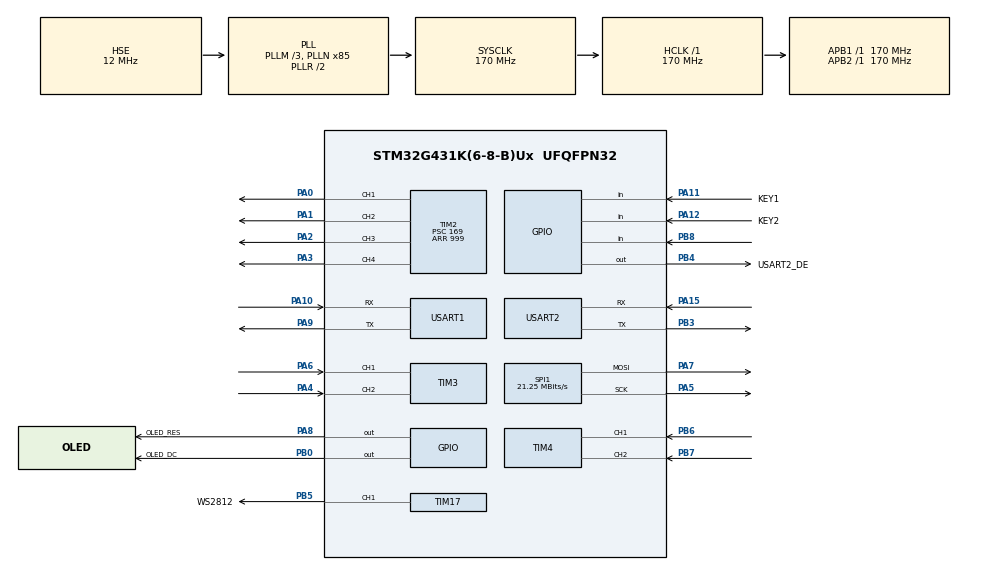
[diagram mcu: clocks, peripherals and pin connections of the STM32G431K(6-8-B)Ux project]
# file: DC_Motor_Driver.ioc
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Dma.Request0=USART1_RX
Dma.Request1=SPI1_TX
Dma.Request2=TIM17_CH1
Dma.Request3=USART2_RX
Dma.SPI1_TX.1.Direction=DMA_MEMORY_TO_PERIPH
Dma.SPI1_TX.1.EventEnable=DISABLE
Dma.SPI1_TX.1.Instance=DMA2_Channel1
Dma.SPI1_TX.1.MemDataAlignment=DMA_MDATAALIGN_BYTE
Dma.SPI1_TX.1.MemInc=DMA_MINC_ENABLE
Dma.SPI1_TX.1.Mode=DMA_NORMAL
Dma.SPI1_TX.1.PeriphDataAlignment=DMA_PDATAALIGN_BYTE
Dma.SPI1_TX.1.PeriphInc=DMA_PINC_DISABLE
Dma.SPI1_TX.1.Polarity=HAL_DMAMUX_REQ_GEN_RISING
Dma.SPI1_TX.1.Priority=DMA_PRIORITY_LOW
Dma.SPI1_TX.1.RequestNumber=1
Dma.SPI1_TX.1.SignalID=NONE
Dma.SPI1_TX.1.SyncEnable=DISABLE
Dma.SPI1_TX.1.SyncPolarity=HAL_DMAMUX_SYNC_NO_EVENT
Dma.SPI1_TX.1.SyncRequestNumber=1
Dma.SPI1_TX.1.SyncSignalID=NONE
Dma.TIM17_CH1.2.Direction=DMA_PERIPH_TO_MEMORY
Dma.TIM17_CH1.2.EventEnable=DISABLE
Dma.TIM17_CH1.2.Instance=DMA2_Channel2
Dma.TIM17_CH1.2.MemDataAlignment=DMA_MDATAALIGN_HALFWORD
Dma.TIM17_CH1.2.MemInc=DMA_MINC_ENABLE
Dma.TIM17_CH1.2.Mode=DMA_NORMAL
Dma.TIM17_CH1.2.PeriphDataAlignment=DMA_PDATAALIGN_HALFWORD
Dma.TIM17_CH1.2.PeriphInc=DMA_PINC_DISABLE
Dma.TIM17_CH1.2.Polarity=HAL_DMAMUX_REQ_GEN_RISING
Dma.TIM17_CH1.2.Priority=DMA_PRIORITY_LOW
Dma.TIM17_CH1.2.RequestNumber=1
Dma.TIM17_CH1.2.SignalID=NONE
Dma.TIM17_CH1.2.SyncEnable=DISABLE
Dma.TIM17_CH1.2.SyncPolarity=HAL_DMAMUX_SYNC_NO_EVENT
Dma.TIM17_CH1.2.SyncRequestNumber=1
Dma.TIM17_CH1.2.SyncSignalID=NONE
Dma.USART1_RX.0.Direction=DMA_PERIPH_TO_MEMORY
Dma.USART1_RX.0.EventEnable=DISABLE
Dma.USART1_RX.0.Instance=DMA1_Channel1
Dma.USART1_RX.0.MemDataAlignment=DMA_MDATAALIGN_BYTE
Dma.USART1_RX.0.MemInc=DMA_MINC_ENABLE
Dma.USART1_RX.0.Mode=DMA_NORMAL
Dma.USART1_RX.0.PeriphDataAlignment=DMA_PDATAALIGN_BYTE
Dma.USART1_RX.0.PeriphInc=DMA_PINC_DISABLE
Dma.USART1_RX.0.Polarity=HAL_DMAMUX_REQ_GEN_RISING
Dma.USART1_RX.0.Priority=DMA_PRIORITY_LOW
Dma.USART1_RX.0.RequestNumber=1
Dma.USART1_RX.0.SignalID=NONE
Dma.USART1_RX.0.SyncEnable=DISABLE
Dma.USART1_RX.0.SyncPolarity=HAL_DMAMUX_SYNC_NO_EVENT
Dma.USART1_RX.0.SyncRequestNumber=1
Dma.USART1_RX.0.SyncSignalID=NONE
Dma.USART2_RX.3.Direction=DMA_PERIPH_TO_MEMORY
Dma.USART2_RX.3.EventEnable=DISABLE
Dma.USART2_RX.3.Instance=DMA1_Channel2
Dma.USART2_RX.3.MemDataAlignment=DMA_MDATAALIGN_BYTE
Dma.USART2_RX.3.MemInc=DMA_MINC_ENABLE
Dma.USART2_RX.3.Mode=DMA_NORMAL
Dma.USART2_RX.3.PeriphDataAlignment=DMA_PDATAALIGN_BYTE
Dma.USART2_RX.3.PeriphInc=DMA_PINC_DISABLE
Dma.USART2_RX.3.Polarity=HAL_DMAMUX_REQ_GEN_RISING
Dma.USART2_RX.3.Priority=DMA_PRIORITY_LOW
Dma.USART2_RX.3.RequestNumber=1
Dma.USART2_RX.3.SignalID=NONE
Dma.USART2_RX.3.SyncEnable=DISABLE
Dma.USART2_RX.3.SyncPolarity=HAL_DMAMUX_SYNC_NO_EVENT
Dma.USART2_RX.3.SyncRequestNumber=1
Dma.USART2_RX.3.SyncSignalID=NONE
Mcu.Family=STM32G4
Mcu.Name=STM32G431K(6-8-B)Ux
Mcu.Package=UFQFPN32
NVIC.DMA1_Channel1_IRQn=true\:0\:0\:false\:false\:true\:false\:true\:true
NVIC.DMA1_Channel2_IRQn=true\:0\:0\:false\:false\:true\:false\:true\:true
NVIC.DMA2_Channel1_IRQn=true\:0\:0\:false\:false\:true\:false\:true\:true
NVIC.DMA2_Channel2_IRQn=true\:0\:0\:false\:false\:true\:false\:true\:true
NVIC.PriorityGroup=NVIC_PRIORITYGROUP_4
NVIC.TIM3_IRQn=true\:0\:0\:false\:false\:true\:true\:true\:true
NVIC.TIM4_IRQn=true\:0\:0\:false\:false\:true\:true\:true\:true
NVIC.TIM6_DAC_IRQn=true\:0\:0\:false\:false\:true\:true\:true\:true
NVIC.USART1_IRQn=true\:0\:0\:false\:false\:true\:true\:true\:true
NVIC.USART2_IRQn=true\:0\:0\:false\:false\:true\:true\:true\:true
PA0.Signal=S_TIM2_CH1
PA1.Signal=S_TIM2_CH2
PA10.Mode=Asynchronous
PA10.Signal=USART1_RX
PA11.GPIO_Label=KEY1
PA11.Signal=GPIO_Input
PA12.GPIO_Label=KEY2
PA12.Signal=GPIO_Input
PA13.Mode=Serial_Wire
PA13.Signal=SYS_JTMS-SWDIO
PA14.Mode=Serial_Wire
PA14.Signal=SYS_JTCK-SWCLK
PA15.Mode=Asynchronous
PA15.Signal=USART2_RX
PA2.Signal=S_TIM2_CH3
PA3.Signal=S_TIM2_CH4
PA4.Signal=S_TIM3_CH2
PA5.Mode=TX_Only_Simplex_Unidirect_Master
PA5.Signal=SPI1_SCK
PA6.Signal=S_TIM3_CH1
PA7.Mode=TX_Only_Simplex_Unidirect_Master
PA7.Signal=SPI1_MOSI
PA8.GPIO_Label=OLED_RES
PA8.Signal=GPIO_Output
PA9.Mode=Asynchronous
PA9.Signal=USART1_TX
PB0.GPIO_Label=OLED_DC
PB0.Signal=GPIO_Output
PB3.Mode=Asynchronous
PB3.Signal=USART2_TX
PB4.GPIO_Label=USART2_DE
PB4.Signal=GPIO_Output
PB5.GPIO_Label=WS2812
PB5.Signal=S_TIM17_CH1
PB6.Signal=S_TIM4_CH1
PB7.Signal=S_TIM4_CH2
PB8-BOOT0.Signal=GPIO_Input
PF0-OSC_IN.Mode=HSE-External-Oscillator
PF0-OSC_IN.Signal=RCC_OSC_IN
PF1-OSC_OUT.Mode=HSE-External-Oscillator
PF1-OSC_OUT.Signal=RCC_OSC_OUT
ProjectManager.HeapSize=0x200
ProjectManager.StackSize=0x400
ProjectManager.TargetToolchain=MDK-ARM V5.32
RCC.ADC12Freq_Value=170000000
RCC.AHBFreq_Value=170000000
RCC.APB1Freq_Value=170000000
RCC.APB1TimFreq_Value=170000000
RCC.APB2Freq_Value=170000000
RCC.APB2TimFreq_Value=170000000
RCC.CortexFreq_Value=170000000
RCC.EXTERNAL_CLOCK_VALUE=12288000
RCC.HCLKFreq_Value=170000000
RCC.HSE_VALUE=12000000
RCC.HSI48_VALUE=48000000
RCC.HSI_VALUE=16000000
RCC.LSE_VALUE=32768
RCC.PLLM=RCC_PLLM_DIV3
RCC.PLLN=85
RCC.PLLSourceVirtual=RCC_PLLSOURCE_HSE
RCC.SYSCLKFreq_VALUE=170000000
RCC.SYSCLKSource=RCC_SYSCLKSOURCE_PLLCLK
RCC.USBFreq_Value=170000000
RCC.VCOOutputFreq_Value=340000000
RTC.AsynchPrediv=31
RTC.SynchPrediv=999
SH.S_TIM17_CH1.0=TIM17_CH1,PWM Generation1 CH1
SH.S_TIM2_CH1.0=TIM2_CH1,PWM Generation1 CH1
SH.S_TIM2_CH2.0=TIM2_CH2,PWM Generation2 CH2
SH.S_TIM2_CH3.0=TIM2_CH3,PWM Generation3 CH3
SH.S_TIM2_CH4.0=TIM2_CH4,PWM Generation4 CH4
SH.S_TIM3_CH1.0=TIM3_CH1,Encoder_Interface
SH.S_TIM3_CH2.0=TIM3_CH2,Encoder_Interface
SH.S_TIM4_CH1.0=TIM4_CH1,Encoder_Interface
SH.S_TIM4_CH2.0=TIM4_CH2,Encoder_Interface
SPI1.BaudRatePrescaler=SPI_BAUDRATEPRESCALER_8
SPI1.CalculateBaudRate=21.25 MBits/s
SPI1.DataSize=SPI_DATASIZE_8BIT
SPI1.Direction=SPI_DIRECTION_2LINES
SPI1.Mode=SPI_MODE_MASTER
SPI1.VirtualType=VM_MASTER
TIM17.Channel=TIM_CHANNEL_1
TIM2.AutoReloadPreload=TIM_AUTORELOAD_PRELOAD_ENABLE
TIM2.Channel-PWM\ Generation1\ CH1=TIM_CHANNEL_1
TIM2.Channel-PWM\ Generation2\ CH2=TIM_CHANNEL_2
TIM2.Channel-PWM\ Generation3\ CH3=TIM_CHANNEL_3
TIM2.Channel-PWM\ Generation4\ CH4=TIM_CHANNEL_4
TIM2.PeriodNoDither=999
TIM2.Prescaler=169
TIM3.EncoderMode=TIM_ENCODERMODE_TI12
TIM3.IC1Polarity=TIM_ICPOLARITY_RISING
TIM3.IC2Polarity=TIM_ICPOLARITY_RISING
TIM4.EncoderMode=TIM_ENCODERMODE_TI12
TIM4.IC1Polarity=TIM_ICPOLARITY_RISING
TIM4.IC2Polarity=TIM_ICPOLARITY_RISING
TIM6.AutoReloadPreload=TIM_AUTORELOAD_PRELOAD_ENABLE
TIM6.PeriodNoDither=999
TIM6.Prescaler=16999
USART1.VirtualMode-Asynchronous=VM_ASYNC
USART2.VirtualMode-Asynchronous=VM_ASYNC
VP_RTC_VS_RTC_Activate.Mode=RTC_Enabled
VP_RTC_VS_RTC_Calendar.Mode=RTC_Calendar
VP_SYS_VS_DBSignals.Mode=DisableDeadBatterySignals
VP_TIM17_VS_ClockSourceINT.Mode=Enable_Timer
VP_TIM2_VS_ClockSourceINT.Mode=Internal
VP_TIM6_VS_ClockSourceINT.Mode=Enable_Timer
board=custom

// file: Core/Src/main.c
/* USER CODE BEGIN Header */
/* USER CODE END Header */
#include "main.h"
#include "dma.h"
#include "rtc.h"
#include "spi.h"
#include "tim.h"
#include "usart.h"
#include "gpio.h"

/* USER CODE BEGIN Includes */
#include "app_main.h"
/* USER CODE END Includes */

void SystemClock_Config(void);

int main(void)
{

  /* MCU Configuration--------------------------------------------------------*/

  /* Reset of all peripherals, Initializes the Flash interface and the Systick. */
  HAL_Init();

  /* Configure the system clock */
  SystemClock_Config();

  /* Initialize all configured peripherals */
  MX_GPIO_Init();
  MX_DMA_Init();
  MX_SPI1_Init();
  MX_TIM2_Init();
  MX_TIM3_Init();
  MX_TIM4_Init();
  MX_TIM17_Init();
  MX_USART1_UART_Init();
  MX_USART2_UART_Init();
  MX_TIM6_Init();
  MX_RTC_Init();
  /* USER CODE BEGIN 2 */

  APP_Main();
  /* USER CODE END 2 */

  /* Infinite loop */
  while (1)
  {

  }
}

void SystemClock_Config(void)
{
  RCC_OscInitTypeDef RCC_OscInitStruct = {0};
  RCC_ClkInitTypeDef RCC_ClkInitStruct = {0};

  /** Configure the main internal regulator output voltage
  */
  HAL_PWREx_ControlVoltageScaling(PWR_REGULATOR_VOLTAGE_SCALE1_BOOST);

  /** Initializes the RCC Oscillators according to the specified parameters
  * in the RCC_OscInitTypeDef structure.
  */
  RCC_OscInitStruct.OscillatorType = RCC_OSCILLATORTYPE_LSI|RCC_OSCILLATORTYPE_HSE;
  RCC_OscInitStruct.HSEState = RCC_HSE_ON;
  RCC_OscInitStruct.LSIState = RCC_LSI_ON;
  RCC_OscInitStruct.PLL.PLLState = RCC_PLL_ON;
  RCC_OscInitStruct.PLL.PLLSource = RCC_PLLSOURCE_HSE;
  RCC_OscInitStruct.PLL.PLLM = RCC_PLLM_DIV3;
  RCC_OscInitStruct.PLL.PLLN = 85;
  RCC_OscInitStruct.PLL.PLLP = RCC_PLLP_DIV2;
  RCC_OscInitStruct.PLL.PLLQ = RCC_PLLQ_DIV2;
  RCC_OscInitStruct.PLL.PLLR = RCC_PLLR_DIV2;
  if (HAL_RCC_OscConfig(&RCC_OscInitStruct) != HAL_OK)
  {
    Error_Handler();
  }

  /** Initializes the CPU, AHB and APB buses clocks
  */
  RCC_ClkInitStruct.ClockType = RCC_CLOCKTYPE_HCLK|RCC_CLOCKTYPE_SYSCLK
                              |RCC_CLOCKTYPE_PCLK1|RCC_CLOCKTYPE_PCLK2;
  RCC_ClkInitStruct.SYSCLKSource = RCC_SYSCLKSOURCE_PLLCLK;
  RCC_ClkInitStruct.AHBCLKDivider = RCC_SYSCLK_DIV1;
  RCC_ClkInitStruct.APB1CLKDivider = RCC_HCLK_DIV1;
  RCC_ClkInitStruct.APB2CLKDivider = RCC_HCLK_DIV1;

  if (HAL_RCC_ClockConfig(&RCC_ClkInitStruct, FLASH_LATENCY_4) != HAL_OK)
  {
    Error_Handler();
  }
}

void Error_Handler(void)
{
  __disable_irq();
  while (1)
  {
  }
}
